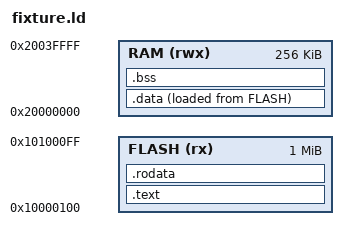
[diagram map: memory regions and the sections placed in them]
ENTRY(_start)
MEMORY
{
    FLASH (rx) : ORIGIN = 0x10000100, LENGTH = 1M
    RAM (rwx)  : ORIGIN = 0x20000000, LENGTH = 256K
}
SECTIONS
{
    .text : { *(.text*) } > FLASH
    .rodata : { *(.rodata*) } > FLASH
    .data : { *(.data*) *(.ramfunc*) } > RAM AT> FLASH
    .bss (NOLOAD) : { *(.bss*) *(COMMON) } > RAM
    /DISCARD/ : { *(.ARM.exidx*) *(.comment) }
}
